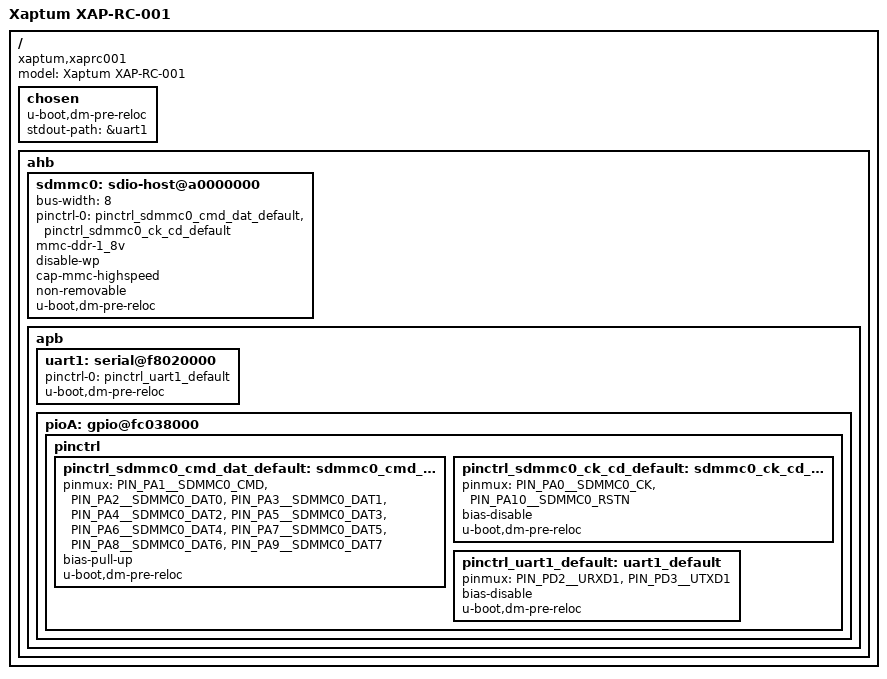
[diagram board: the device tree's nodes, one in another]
/dts-v1/;
#include "sama5d2.dtsi"
#include "sama5d2-pinfunc.h"

/ {
	model = "Xaptum XAP-RC-001";
	compatible = "xaptum,xaprc001", "atmel,sama5d2", "atmel,sama5";

	chosen {
		u-boot,dm-pre-reloc;
		stdout-path = &uart1;
	};

	ahb {
		sdmmc0: sdio-host@a0000000 {
			bus-width = <8>;
			pinctrl-names = "default";
			pinctrl-0 = <&pinctrl_sdmmc0_cmd_dat_default &pinctrl_sdmmc0_ck_cd_default>;
			mmc-ddr-1_8v;
			disable-wp;
			cap-mmc-highspeed;
			/* DAB: Need to try to use higher speed:
				sd-uhs-sdr50, sd-uhs-sdr104, sd-uhs-ddr50 */
			non-removable;
			status = "okay";
			u-boot,dm-pre-reloc;
		};

		apb {
			uart1: serial@f8020000 {
				pinctrl-names = "default";
				pinctrl-0 = <&pinctrl_uart1_default>;
				status = "okay";
				u-boot,dm-pre-reloc;
			};

			pioA: gpio@fc038000 {
				pinctrl {
					pinctrl_sdmmc0_cmd_dat_default: sdmmc0_cmd_dat_default {
						pinmux = <PIN_PA1__SDMMC0_CMD>,
							 <PIN_PA2__SDMMC0_DAT0>,
							 <PIN_PA3__SDMMC0_DAT1>,
							 <PIN_PA4__SDMMC0_DAT2>,
							 <PIN_PA5__SDMMC0_DAT3>,
							 <PIN_PA6__SDMMC0_DAT4>,
							 <PIN_PA7__SDMMC0_DAT5>,
							 <PIN_PA8__SDMMC0_DAT6>,
							 <PIN_PA9__SDMMC0_DAT7>;
						bias-pull-up;
						u-boot,dm-pre-reloc;
					};

					pinctrl_sdmmc0_ck_cd_default: sdmmc0_ck_cd_default {
						pinmux = <PIN_PA0__SDMMC0_CK>,
							 <PIN_PA10__SDMMC0_RSTN>;
						bias-disable;
						u-boot,dm-pre-reloc;
					};

					pinctrl_uart1_default: uart1_default {
						pinmux = <PIN_PD2__URXD1>,
							 <PIN_PD3__UTXD1>;
						bias-disable;
						u-boot,dm-pre-reloc;
					};

				};
			};
		};
	};
};
